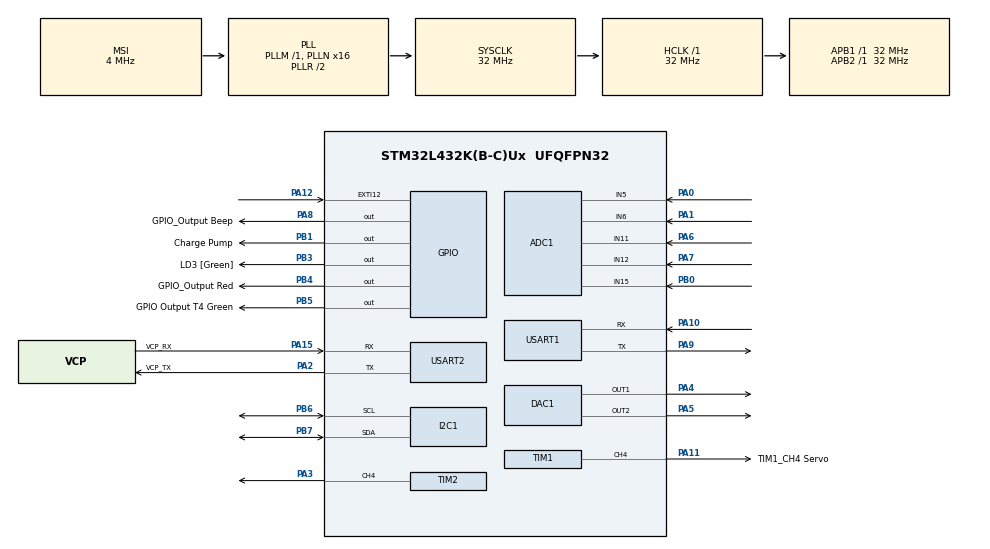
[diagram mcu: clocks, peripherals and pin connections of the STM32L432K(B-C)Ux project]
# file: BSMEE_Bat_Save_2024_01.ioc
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ADC1.Channel-0\#ChannelRegularConversion=ADC_CHANNEL_11
ADC1.Channel-1\#ChannelRegularConversion=ADC_CHANNEL_12
ADC1.Channel-2\#ChannelRegularConversion=ADC_CHANNEL_15
ADC1.Channel-3\#ChannelRegularConversion=ADC_CHANNEL_6
ADC1.Channel-4\#ChannelRegularConversion=ADC_CHANNEL_5
ADC1.ClockPrescaler=ADC_CLOCK_ASYNC_DIV16
ADC1.ContinuousConvMode=ENABLE
ADC1.DMAContinuousRequests=ENABLE
ADC1.EOCSelection=ADC_EOC_SEQ_CONV
ADC1.NbrOfConversion=5
ADC1.NbrOfConversionFlag=1
ADC1.OffsetNumber-0\#ChannelRegularConversion=ADC_OFFSET_NONE
ADC1.OffsetNumber-1\#ChannelRegularConversion=ADC_OFFSET_NONE
ADC1.OffsetNumber-2\#ChannelRegularConversion=ADC_OFFSET_NONE
ADC1.OffsetNumber-3\#ChannelRegularConversion=ADC_OFFSET_NONE
ADC1.OffsetNumber-4\#ChannelRegularConversion=ADC_OFFSET_NONE
ADC1.Overrun=ADC_OVR_DATA_OVERWRITTEN
ADC1.Rank-0\#ChannelRegularConversion=1
ADC1.Rank-1\#ChannelRegularConversion=2
ADC1.Rank-2\#ChannelRegularConversion=3
ADC1.Rank-3\#ChannelRegularConversion=4
ADC1.Rank-4\#ChannelRegularConversion=5
ADC1.SamplingTime-0\#ChannelRegularConversion=ADC_SAMPLETIME_247CYCLES_5
ADC1.SamplingTime-1\#ChannelRegularConversion=ADC_SAMPLETIME_247CYCLES_5
ADC1.SamplingTime-2\#ChannelRegularConversion=ADC_SAMPLETIME_247CYCLES_5
ADC1.SamplingTime-3\#ChannelRegularConversion=ADC_SAMPLETIME_247CYCLES_5
ADC1.SamplingTime-4\#ChannelRegularConversion=ADC_SAMPLETIME_247CYCLES_5
ADC1.master=1
DAC1.DAC_Channel-DAC_OUT2=DAC_CHANNEL_2
Dma.ADC1.4.Direction=DMA_PERIPH_TO_MEMORY
Dma.ADC1.4.Instance=DMA1_Channel1
Dma.ADC1.4.MemDataAlignment=DMA_MDATAALIGN_HALFWORD
Dma.ADC1.4.MemInc=DMA_MINC_ENABLE
Dma.ADC1.4.Mode=DMA_CIRCULAR
Dma.ADC1.4.PeriphDataAlignment=DMA_PDATAALIGN_HALFWORD
Dma.ADC1.4.PeriphInc=DMA_PINC_DISABLE
Dma.ADC1.4.Priority=DMA_PRIORITY_LOW
Dma.Request0=USART1_RX
Dma.Request1=USART1_TX
Dma.Request2=USART2_RX
Dma.Request3=USART2_TX
Dma.Request4=ADC1
Dma.USART1_RX.0.Direction=DMA_PERIPH_TO_MEMORY
Dma.USART1_RX.0.Instance=DMA1_Channel5
Dma.USART1_RX.0.MemDataAlignment=DMA_MDATAALIGN_BYTE
Dma.USART1_RX.0.MemInc=DMA_MINC_ENABLE
Dma.USART1_RX.0.Mode=DMA_NORMAL
Dma.USART1_RX.0.PeriphDataAlignment=DMA_PDATAALIGN_BYTE
Dma.USART1_RX.0.PeriphInc=DMA_PINC_DISABLE
Dma.USART1_RX.0.Priority=DMA_PRIORITY_LOW
Dma.USART1_TX.1.Direction=DMA_MEMORY_TO_PERIPH
Dma.USART1_TX.1.Instance=DMA1_Channel4
Dma.USART1_TX.1.MemDataAlignment=DMA_MDATAALIGN_BYTE
Dma.USART1_TX.1.MemInc=DMA_MINC_ENABLE
Dma.USART1_TX.1.Mode=DMA_NORMAL
Dma.USART1_TX.1.PeriphDataAlignment=DMA_PDATAALIGN_BYTE
Dma.USART1_TX.1.PeriphInc=DMA_PINC_DISABLE
Dma.USART1_TX.1.Priority=DMA_PRIORITY_LOW
Dma.USART2_RX.2.Direction=DMA_PERIPH_TO_MEMORY
Dma.USART2_RX.2.Instance=DMA1_Channel6
Dma.USART2_RX.2.MemDataAlignment=DMA_MDATAALIGN_BYTE
Dma.USART2_RX.2.MemInc=DMA_MINC_ENABLE
Dma.USART2_RX.2.Mode=DMA_NORMAL
Dma.USART2_RX.2.PeriphDataAlignment=DMA_PDATAALIGN_BYTE
Dma.USART2_RX.2.PeriphInc=DMA_PINC_DISABLE
Dma.USART2_RX.2.Priority=DMA_PRIORITY_LOW
Dma.USART2_TX.3.Direction=DMA_MEMORY_TO_PERIPH
Dma.USART2_TX.3.Instance=DMA1_Channel7
Dma.USART2_TX.3.MemDataAlignment=DMA_MDATAALIGN_BYTE
Dma.USART2_TX.3.MemInc=DMA_MINC_ENABLE
Dma.USART2_TX.3.Mode=DMA_NORMAL
Dma.USART2_TX.3.PeriphDataAlignment=DMA_PDATAALIGN_BYTE
Dma.USART2_TX.3.PeriphInc=DMA_PINC_DISABLE
Dma.USART2_TX.3.Priority=DMA_PRIORITY_LOW
I2C1.Timing=0x00707CBB
Mcu.Family=STM32L4
Mcu.Name=STM32L432K(B-C)Ux
Mcu.Package=UFQFPN32
NVIC.ADC1_IRQn=true\:0\:0\:false\:false\:true\:true\:true\:true
NVIC.DMA1_Channel1_IRQn=true\:0\:0\:false\:false\:true\:false\:true\:true
NVIC.DMA1_Channel4_IRQn=true\:0\:0\:false\:false\:true\:false\:true\:true
NVIC.DMA1_Channel5_IRQn=true\:0\:0\:false\:false\:true\:false\:true\:true
NVIC.DMA1_Channel6_IRQn=true\:0\:0\:false\:false\:true\:false\:true\:true
NVIC.DMA1_Channel7_IRQn=true\:0\:0\:false\:false\:true\:false\:true\:true
NVIC.PriorityGroup=NVIC_PRIORITYGROUP_4
NVIC.TIM6_DAC_IRQn=true\:0\:0\:false\:false\:true\:true\:true\:true
NVIC.USART1_IRQn=true\:0\:0\:false\:false\:true\:true\:true\:true
NVIC.USART2_IRQn=true\:0\:0\:false\:false\:true\:true\:true\:true
PA0.Signal=ADCx_IN5
PA1.Signal=ADCx_IN6
PA10.Mode=Asynchronous
PA10.Signal=USART1_RX
PA11.GPIO_Label=TIM1_CH4 Servo
PA11.Signal=S_TIM1_CH4
PA12.Signal=GPXTI12
PA13\ (JTMS-SWDIO).GPIO_Label=SWDIO
PA13\ (JTMS-SWDIO).Mode=Serial_Wire
PA13\ (JTMS-SWDIO).Signal=SYS_JTMS-SWDIO
PA14\ (JTCK-SWCLK).GPIO_Label=SWCLK
PA14\ (JTCK-SWCLK).Mode=Serial_Wire
PA14\ (JTCK-SWCLK).Signal=SYS_JTCK-SWCLK
PA15\ (JTDI).GPIO_Label=VCP_RX
PA15\ (JTDI).Mode=Asynchronous
PA15\ (JTDI).Signal=USART2_RX
PA2.GPIO_Label=VCP_TX
PA2.Mode=Asynchronous
PA2.Signal=USART2_TX
PA3.Signal=S_TIM2_CH4
PA4.Signal=COMP_DAC11_group
PA5.Signal=COMP_DAC12_group
PA6.Signal=ADCx_IN11
PA7.Signal=ADCx_IN12
PA8.GPIO_Label=GPIO_Output Beep
PA8.Signal=GPIO_Output
PA9.Mode=Asynchronous
PA9.Signal=USART1_TX
PB0.Signal=ADCx_IN15
PB1.GPIO_Label=Charge Pump
PB1.Signal=GPIO_Output
PB3\ (JTDO-TRACESWO).GPIO_Label=LD3 [Green]
PB3\ (JTDO-TRACESWO).Signal=GPIO_Output
PB4\ (NJTRST).GPIO_Label=GPIO_Output Red
PB4\ (NJTRST).Signal=GPIO_Output
PB5.GPIO_Label=GPIO Output T4 Green
PB5.Signal=GPIO_Output
PB6.Mode=I2C
PB6.Signal=I2C1_SCL
PB7.Mode=I2C
PB7.Signal=I2C1_SDA
PC14-OSC32_IN\ (PC14).Mode=LSE-External-Oscillator
PC14-OSC32_IN\ (PC14).Signal=RCC_OSC32_IN
PC15-OSC32_OUT\ (PC15).Mode=LSE-External-Oscillator
PC15-OSC32_OUT\ (PC15).Signal=RCC_OSC32_OUT
ProjectManager.HeapSize=0x200
ProjectManager.StackSize=0x400
ProjectManager.TargetToolchain=STM32CubeIDE
RCC.ADCFreq_Value=32000000
RCC.AHBFreq_Value=32000000
RCC.APB1Freq_Value=32000000
RCC.APB1TimFreq_Value=32000000
RCC.APB2Freq_Value=32000000
RCC.APB2TimFreq_Value=32000000
RCC.CortexFreq_Value=32000000
RCC.HCLKFreq_Value=32000000
RCC.HSE_VALUE=8000000
RCC.HSI16_VALUE=16000000
RCC.HSI48_VALUE=48000000
RCC.HSI_VALUE=16000000
RCC.MSI_VALUE=4000000
RCC.PLLMUL=RCC_PLLMUL_4
RCC.PLLN=16
RCC.PLLSAI1N=16
RCC.SYSCLKFreq_VALUE=32000000
RCC.SYSCLKSource=RCC_SYSCLKSOURCE_PLLCLK
RCC.USBFreq_Value=32000000
RCC.VCOOutputFreq_Value=64000000
SH.ADCx_IN11.0=ADC1_IN11,IN11-Single-Ended
SH.ADCx_IN12.0=ADC1_IN12,IN12-Single-Ended
SH.ADCx_IN15.0=ADC1_IN15,IN15-Single-Ended
SH.ADCx_IN5.0=ADC1_IN5,IN5-Single-Ended
SH.ADCx_IN6.0=ADC1_IN6,IN6-Single-Ended
SH.COMP_DAC11_group.0=DAC1_OUT1,DAC_OUT1
SH.COMP_DAC12_group.0=DAC1_OUT2,DAC_OUT2
SH.S_TIM1_CH4.0=TIM1_CH4,PWM Generation4 CH4
SH.S_TIM2_CH4.0=TIM2_CH4,PWM Generation4 CH4
TIM1.Channel-PWM\ Generation4\ CH4=TIM_CHANNEL_4
TIM2.AutoReloadPreload=TIM_AUTORELOAD_PRELOAD_ENABLE
TIM2.Channel-PWM\ Generation4\ CH4=TIM_CHANNEL_4
TIM2.OCPolarity_4=TIM_OCPOLARITY_LOW
TIM2.Period=1023
TIM2.Prescaler=1
TIM2.Pulse-PWM\ Generation4\ CH4=100
TIM6.AutoReloadPreload=TIM_AUTORELOAD_PRELOAD_ENABLE
TIM6.Period=1000 - 1
TIM6.Prescaler=32 - 1
USART1.VirtualMode-Asynchronous=VM_ASYNC
USART2.VirtualMode-Asynchronous=VM_ASYNC
VP_RTC_VS_RTC_Activate.Mode=RTC_Enabled
VP_RTC_VS_RTC_Calendar.Mode=RTC_Calendar
VP_TIM2_VS_ClockSourceINT.Mode=Internal
VP_TIM6_VS_ClockSourceINT.Mode=Enable_Timer
board=NUCLEO-L432KC

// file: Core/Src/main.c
/* USER CODE BEGIN Header */
/**
 *  Jon Freeman B Eng Hons
 *
 * WARNING
 * Code created using STM32CubeIDE from ST Microelectronics.
 * THIS FILE IS A MIX OF MACHINE-GENERATED / MAN-MADE CODE including most of the startup code
 *
 * YOU ARE STRONGLY ADVISED NOT TO EDIT THIS FILE
 *
  ******************************************************************************
  * @file           : main.c
  * @brief          : Main program body
  ******************************************************************************
  * @attention
  *
  * Copyright (c) 2024 STMicroelectronics.
  * All rights reserved.
  *
  * This software is licensed under terms that can be found in the LICENSE file
  * in the root directory of this software component.
  * If no LICENSE file comes with this software, it is provided AS-IS.
  *
  ******************************************************************************
  */
/* USER CODE END Header */
#include "main.h"

/* USER CODE BEGIN Includes */
#include	<stdbool.h>

/* USER CODE END Includes */

ADC_HandleTypeDef hadc1;
DMA_HandleTypeDef hdma_adc1;

DAC_HandleTypeDef hdac1;

I2C_HandleTypeDef hi2c1;

RTC_HandleTypeDef hrtc;

TIM_HandleTypeDef htim1;
TIM_HandleTypeDef htim2;
TIM_HandleTypeDef htim6;

UART_HandleTypeDef huart1;
UART_HandleTypeDef huart2;
DMA_HandleTypeDef hdma_usart1_rx;
DMA_HandleTypeDef hdma_usart1_tx;
DMA_HandleTypeDef hdma_usart2_rx;
DMA_HandleTypeDef hdma_usart2_tx;

void SystemClock_Config(void);
static void MX_GPIO_Init(void);
static void MX_DMA_Init(void);
static void MX_USART2_UART_Init(void);
static void MX_ADC1_Init(void);
static void MX_DAC1_Init(void);
static void MX_I2C1_Init(void);
static void MX_USART1_UART_Init(void);
static void MX_TIM1_Init(void);
static void MX_TIM2_Init(void);
static void MX_TIM6_Init(void);
static void MX_RTC_Init(void);
/* USER CODE BEGIN PFP */
extern	void	ForeverLoop	()	;

/* USER CODE END PFP */

int main(void)
{

  /* MCU Configuration--------------------------------------------------------*/

  /* Reset of all peripherals, Initializes the Flash interface and the Systick. */
  HAL_Init();

  /* Configure the system clock */
  SystemClock_Config();

  /* Initialize all configured peripherals */
  MX_GPIO_Init();
  MX_DMA_Init();
  MX_USART2_UART_Init();
  MX_ADC1_Init();
  MX_DAC1_Init();
  MX_I2C1_Init();
  MX_USART1_UART_Init();
  MX_TIM1_Init();
  MX_TIM2_Init();
  MX_TIM6_Init();
  MX_RTC_Init();
  /* USER CODE BEGIN 2 */
  HAL_TIM_Base_Start_IT(&htim6);	//	Need this to start timer

  ForeverLoop	();		//	Leave main.c, into 'C++', never to return

  /* USER CODE END 2 */

  /* Infinite loop */
  while (1)
  {

  }
}

void SystemClock_Config(void)
{
  RCC_OscInitTypeDef RCC_OscInitStruct = {0};
  RCC_ClkInitTypeDef RCC_ClkInitStruct = {0};

  /** Configure the main internal regulator output voltage
  */
  if (HAL_PWREx_ControlVoltageScaling(PWR_REGULATOR_VOLTAGE_SCALE1) != HAL_OK)
  {
    Error_Handler();
  }

  /** Configure LSE Drive Capability
  */
  HAL_PWR_EnableBkUpAccess();
  __HAL_RCC_LSEDRIVE_CONFIG(RCC_LSEDRIVE_LOW);

  /** Initializes the RCC Oscillators according to the specified parameters
  * in the RCC_OscInitTypeDef structure.
  */
  RCC_OscInitStruct.OscillatorType = RCC_OSCILLATORTYPE_LSI|RCC_OSCILLATORTYPE_LSE
                              |RCC_OSCILLATORTYPE_MSI;
  RCC_OscInitStruct.LSEState = RCC_LSE_ON;
  RCC_OscInitStruct.LSIState = RCC_LSI_ON;
  RCC_OscInitStruct.MSIState = RCC_MSI_ON;
  RCC_OscInitStruct.MSICalibrationValue = 0;
  RCC_OscInitStruct.MSIClockRange = RCC_MSIRANGE_6;
  RCC_OscInitStruct.PLL.PLLState = RCC_PLL_ON;
  RCC_OscInitStruct.PLL.PLLSource = RCC_PLLSOURCE_MSI;
  RCC_OscInitStruct.PLL.PLLM = 1;
  RCC_OscInitStruct.PLL.PLLN = 16;
  RCC_OscInitStruct.PLL.PLLP = RCC_PLLP_DIV7;
  RCC_OscInitStruct.PLL.PLLQ = RCC_PLLQ_DIV2;
  RCC_OscInitStruct.PLL.PLLR = RCC_PLLR_DIV2;
  if (HAL_RCC_OscConfig(&RCC_OscInitStruct) != HAL_OK)
  {
    Error_Handler();
  }

  /** Initializes the CPU, AHB and APB buses clocks
  */
  RCC_ClkInitStruct.ClockType = RCC_CLOCKTYPE_HCLK|RCC_CLOCKTYPE_SYSCLK
                              |RCC_CLOCKTYPE_PCLK1|RCC_CLOCKTYPE_PCLK2;
  RCC_ClkInitStruct.SYSCLKSource = RCC_SYSCLKSOURCE_PLLCLK;
  RCC_ClkInitStruct.AHBCLKDivider = RCC_SYSCLK_DIV1;
  RCC_ClkInitStruct.APB1CLKDivider = RCC_HCLK_DIV1;
  RCC_ClkInitStruct.APB2CLKDivider = RCC_HCLK_DIV1;

  if (HAL_RCC_ClockConfig(&RCC_ClkInitStruct, FLASH_LATENCY_1) != HAL_OK)
  {
    Error_Handler();
  }

  /** Enable MSI Auto calibration
  */
  HAL_RCCEx_EnableMSIPLLMode();
}

static void MX_ADC1_Init(void)
{

  ADC_ChannelConfTypeDef sConfig = {0};

  /** Common config
  */
  hadc1.Instance = ADC1;
  hadc1.Init.ClockPrescaler = ADC_CLOCK_ASYNC_DIV16;
  hadc1.Init.Resolution = ADC_RESOLUTION_12B;
  hadc1.Init.DataAlign = ADC_DATAALIGN_RIGHT;
  hadc1.Init.ScanConvMode = ADC_SCAN_ENABLE;
  hadc1.Init.EOCSelection = ADC_EOC_SEQ_CONV;
  hadc1.Init.LowPowerAutoWait = DISABLE;
  hadc1.Init.ContinuousConvMode = ENABLE;
  hadc1.Init.NbrOfConversion = 5;
  hadc1.Init.DiscontinuousConvMode = DISABLE;
  hadc1.Init.ExternalTrigConv = ADC_SOFTWARE_START;
  hadc1.Init.ExternalTrigConvEdge = ADC_EXTERNALTRIGCONVEDGE_NONE;
  hadc1.Init.DMAContinuousRequests = ENABLE;
  hadc1.Init.Overrun = ADC_OVR_DATA_OVERWRITTEN;
  hadc1.Init.OversamplingMode = DISABLE;
  if (HAL_ADC_Init(&hadc1) != HAL_OK)
  {
    Error_Handler();
  }

  /** Configure Regular Channel
  */
  sConfig.Channel = ADC_CHANNEL_11;
  sConfig.Rank = ADC_REGULAR_RANK_1;
  sConfig.SamplingTime = ADC_SAMPLETIME_247CYCLES_5;
  sConfig.SingleDiff = ADC_SINGLE_ENDED;
  sConfig.OffsetNumber = ADC_OFFSET_NONE;
  sConfig.Offset = 0;
  if (HAL_ADC_ConfigChannel(&hadc1, &sConfig) != HAL_OK)
  {
    Error_Handler();
  }

  /** Configure Regular Channel
  */
  sConfig.Channel = ADC_CHANNEL_12;
  sConfig.Rank = ADC_REGULAR_RANK_2;
  if (HAL_ADC_ConfigChannel(&hadc1, &sConfig) != HAL_OK)
  {
    Error_Handler();
  }

  /** Configure Regular Channel
  */
  sConfig.Channel = ADC_CHANNEL_15;
  sConfig.Rank = ADC_REGULAR_RANK_3;
  if (HAL_ADC_ConfigChannel(&hadc1, &sConfig) != HAL_OK)
  {
    Error_Handler();
  }

  /** Configure Regular Channel
  */
  sConfig.Channel = ADC_CHANNEL_6;
  sConfig.Rank = ADC_REGULAR_RANK_4;
  if (HAL_ADC_ConfigChannel(&hadc1, &sConfig) != HAL_OK)
  {
    Error_Handler();
  }

  /** Configure Regular Channel
  */
  sConfig.Channel = ADC_CHANNEL_5;
  sConfig.Rank = ADC_REGULAR_RANK_5;
  if (HAL_ADC_ConfigChannel(&hadc1, &sConfig) != HAL_OK)
  {
    Error_Handler();
  }

}

static void MX_DAC1_Init(void)
{

  DAC_ChannelConfTypeDef sConfig = {0};

  /** DAC Initialization
  */
  hdac1.Instance = DAC1;
  if (HAL_DAC_Init(&hdac1) != HAL_OK)
  {
    Error_Handler();
  }

  /** DAC channel OUT1 config
  */
  sConfig.DAC_SampleAndHold = DAC_SAMPLEANDHOLD_DISABLE;
  sConfig.DAC_Trigger = DAC_TRIGGER_NONE;
  sConfig.DAC_OutputBuffer = DAC_OUTPUTBUFFER_ENABLE;
  sConfig.DAC_ConnectOnChipPeripheral = DAC_CHIPCONNECT_DISABLE;
  sConfig.DAC_UserTrimming = DAC_TRIMMING_FACTORY;
  if (HAL_DAC_ConfigChannel(&hdac1, &sConfig, DAC_CHANNEL_1) != HAL_OK)
  {
    Error_Handler();
  }

  /** DAC channel OUT2 config
  */
  if (HAL_DAC_ConfigChannel(&hdac1, &sConfig, DAC_CHANNEL_2) != HAL_OK)
  {
    Error_Handler();
  }

}

static void MX_I2C1_Init(void)
{

  hi2c1.Instance = I2C1;
  hi2c1.Init.Timing = 0x00707CBB;
  hi2c1.Init.OwnAddress1 = 0;
  hi2c1.Init.AddressingMode = I2C_ADDRESSINGMODE_7BIT;
  hi2c1.Init.DualAddressMode = I2C_DUALADDRESS_DISABLE;
  hi2c1.Init.OwnAddress2 = 0;
  hi2c1.Init.OwnAddress2Masks = I2C_OA2_NOMASK;
  hi2c1.Init.GeneralCallMode = I2C_GENERALCALL_DISABLE;
  hi2c1.Init.NoStretchMode = I2C_NOSTRETCH_DISABLE;
  if (HAL_I2C_Init(&hi2c1) != HAL_OK)
  {
    Error_Handler();
  }

  /** Configure Analogue filter
  */
  if (HAL_I2CEx_ConfigAnalogFilter(&hi2c1, I2C_ANALOGFILTER_ENABLE) != HAL_OK)
  {
    Error_Handler();
  }

  /** Configure Digital filter
  */
  if (HAL_I2CEx_ConfigDigitalFilter(&hi2c1, 0) != HAL_OK)
  {
    Error_Handler();
  }

}

static void MX_RTC_Init(void)
{

  RTC_TimeTypeDef sTime = {0};
  RTC_DateTypeDef sDate = {0};

  /** Initialize RTC Only
  */
  hrtc.Instance = RTC;
  hrtc.Init.HourFormat = RTC_HOURFORMAT_24;
  hrtc.Init.AsynchPrediv = 127;
  hrtc.Init.SynchPrediv = 255;
  hrtc.Init.OutPut = RTC_OUTPUT_DISABLE;
  hrtc.Init.OutPutRemap = RTC_OUTPUT_REMAP_NONE;
  hrtc.Init.OutPutPolarity = RTC_OUTPUT_POLARITY_HIGH;
  hrtc.Init.OutPutType = RTC_OUTPUT_TYPE_OPENDRAIN;
  if (HAL_RTC_Init(&hrtc) != HAL_OK)
  {
    Error_Handler();
  }

  /** Initialize RTC and set the Time and Date
  */
  sTime.Hours = 0x0;
  sTime.Minutes = 0x0;
  sTime.Seconds = 0x0;
  sTime.DayLightSaving = RTC_DAYLIGHTSAVING_NONE;
  sTime.StoreOperation = RTC_STOREOPERATION_RESET;
  if (HAL_RTC_SetTime(&hrtc, &sTime, RTC_FORMAT_BCD) != HAL_OK)
  {
    Error_Handler();
  }
  sDate.WeekDay = RTC_WEEKDAY_MONDAY;
  sDate.Month = RTC_MONTH_JANUARY;
  sDate.Date = 0x1;
  sDate.Year = 0x0;

  if (HAL_RTC_SetDate(&hrtc, &sDate, RTC_FORMAT_BCD) != HAL_OK)
  {
    Error_Handler();
  }

}

static void MX_TIM1_Init(void)
{

  TIM_MasterConfigTypeDef sMasterConfig = {0};
  TIM_OC_InitTypeDef sConfigOC = {0};
  TIM_BreakDeadTimeConfigTypeDef sBreakDeadTimeConfig = {0};

  htim1.Instance = TIM1;
  htim1.Init.Prescaler = 0;
  htim1.Init.CounterMode = TIM_COUNTERMODE_UP;
  htim1.Init.Period = 65535;
  htim1.Init.ClockDivision = TIM_CLOCKDIVISION_DIV1;
  htim1.Init.RepetitionCounter = 0;
  htim1.Init.AutoReloadPreload = TIM_AUTORELOAD_PRELOAD_DISABLE;
  if (HAL_TIM_PWM_Init(&htim1) != HAL_OK)
  {
    Error_Handler();
  }
  sMasterConfig.MasterOutputTrigger = TIM_TRGO_RESET;
  sMasterConfig.MasterOutputTrigger2 = TIM_TRGO2_RESET;
  sMasterConfig.MasterSlaveMode = TIM_MASTERSLAVEMODE_DISABLE;
  if (HAL_TIMEx_MasterConfigSynchronization(&htim1, &sMasterConfig) != HAL_OK)
  {
    Error_Handler();
  }
  sConfigOC.OCMode = TIM_OCMODE_PWM1;
  sConfigOC.Pulse = 0;
  sConfigOC.OCPolarity = TIM_OCPOLARITY_HIGH;
  sConfigOC.OCFastMode = TIM_OCFAST_DISABLE;
  sConfigOC.OCIdleState = TIM_OCIDLESTATE_RESET;
  sConfigOC.OCNIdleState = TIM_OCNIDLESTATE_RESET;
  if (HAL_TIM_PWM_ConfigChannel(&htim1, &sConfigOC, TIM_CHANNEL_4) != HAL_OK)
  {
    Error_Handler();
  }
  sBreakDeadTimeConfig.OffStateRunMode = TIM_OSSR_DISABLE;
  sBreakDeadTimeConfig.OffStateIDLEMode = TIM_OSSI_DISABLE;
  sBreakDeadTimeConfig.LockLevel = TIM_LOCKLEVEL_OFF;
  sBreakDeadTimeConfig.DeadTime = 0;
  sBreakDeadTimeConfig.BreakState = TIM_BREAK_DISABLE;
  sBreakDeadTimeConfig.BreakPolarity = TIM_BREAKPOLARITY_HIGH;
  sBreakDeadTimeConfig.BreakFilter = 0;
  sBreakDeadTimeConfig.Break2State = TIM_BREAK2_DISABLE;
  sBreakDeadTimeConfig.Break2Polarity = TIM_BREAK2POLARITY_HIGH;
  sBreakDeadTimeConfig.Break2Filter = 0;
  sBreakDeadTimeConfig.AutomaticOutput = TIM_AUTOMATICOUTPUT_DISABLE;
  if (HAL_TIMEx_ConfigBreakDeadTime(&htim1, &sBreakDeadTimeConfig) != HAL_OK)
  {
    Error_Handler();
  }
  HAL_TIM_MspPostInit(&htim1);

}

static void MX_TIM2_Init(void)
{

  TIM_ClockConfigTypeDef sClockSourceConfig = {0};
  TIM_MasterConfigTypeDef sMasterConfig = {0};
  TIM_OC_InitTypeDef sConfigOC = {0};

  htim2.Instance = TIM2;
  htim2.Init.Prescaler = 1;
  htim2.Init.CounterMode = TIM_COUNTERMODE_UP;
  htim2.Init.Period = 1023;
  htim2.Init.ClockDivision = TIM_CLOCKDIVISION_DIV1;
  htim2.Init.AutoReloadPreload = TIM_AUTORELOAD_PRELOAD_ENABLE;
  if (HAL_TIM_Base_Init(&htim2) != HAL_OK)
  {
    Error_Handler();
  }
  sClockSourceConfig.ClockSource = TIM_CLOCKSOURCE_INTERNAL;
  if (HAL_TIM_ConfigClockSource(&htim2, &sClockSourceConfig) != HAL_OK)
  {
    Error_Handler();
  }
  if (HAL_TIM_PWM_Init(&htim2) != HAL_OK)
  {
    Error_Handler();
  }
  sMasterConfig.MasterOutputTrigger = TIM_TRGO_RESET;
  sMasterConfig.MasterSlaveMode = TIM_MASTERSLAVEMODE_DISABLE;
  if (HAL_TIMEx_MasterConfigSynchronization(&htim2, &sMasterConfig) != HAL_OK)
  {
    Error_Handler();
  }
  sConfigOC.OCMode = TIM_OCMODE_PWM1;
  sConfigOC.Pulse = 100;
  sConfigOC.OCPolarity = TIM_OCPOLARITY_LOW;
  sConfigOC.OCFastMode = TIM_OCFAST_DISABLE;
  if (HAL_TIM_PWM_ConfigChannel(&htim2, &sConfigOC, TIM_CHANNEL_4) != HAL_OK)
  {
    Error_Handler();
  }
  HAL_TIM_MspPostInit(&htim2);

}

static void MX_TIM6_Init(void)
{

  TIM_MasterConfigTypeDef sMasterConfig = {0};

  htim6.Instance = TIM6;
  htim6.Init.Prescaler = 32 - 1;
  htim6.Init.CounterMode = TIM_COUNTERMODE_UP;
  htim6.Init.Period = 1000 - 1;
  htim6.Init.AutoReloadPreload = TIM_AUTORELOAD_PRELOAD_ENABLE;
  if (HAL_TIM_Base_Init(&htim6) != HAL_OK)
  {
    Error_Handler();
  }
  sMasterConfig.MasterOutputTrigger = TIM_TRGO_RESET;
  sMasterConfig.MasterSlaveMode = TIM_MASTERSLAVEMODE_DISABLE;
  if (HAL_TIMEx_MasterConfigSynchronization(&htim6, &sMasterConfig) != HAL_OK)
  {
    Error_Handler();
  }

}

static void MX_USART1_UART_Init(void)
{

  huart1.Instance = USART1;
  huart1.Init.BaudRate = 115200;
  huart1.Init.WordLength = UART_WORDLENGTH_8B;
  huart1.Init.StopBits = UART_STOPBITS_1;
  huart1.Init.Parity = UART_PARITY_NONE;
  huart1.Init.Mode = UART_MODE_TX_RX;
  huart1.Init.HwFlowCtl = UART_HWCONTROL_NONE;
  huart1.Init.OverSampling = UART_OVERSAMPLING_16;
  huart1.Init.OneBitSampling = UART_ONE_BIT_SAMPLE_DISABLE;
  huart1.AdvancedInit.AdvFeatureInit = UART_ADVFEATURE_NO_INIT;
  if (HAL_UART_Init(&huart1) != HAL_OK)
  {
    Error_Handler();
  }

}

static void MX_USART2_UART_Init(void)
{

  huart2.Instance = USART2;
  huart2.Init.BaudRate = 115200;
  huart2.Init.WordLength = UART_WORDLENGTH_8B;
  huart2.Init.StopBits = UART_STOPBITS_1;
  huart2.Init.Parity = UART_PARITY_NONE;
  huart2.Init.Mode = UART_MODE_TX_RX;
  huart2.Init.HwFlowCtl = UART_HWCONTROL_NONE;
  huart2.Init.OverSampling = UART_OVERSAMPLING_16;
  huart2.Init.OneBitSampling = UART_ONE_BIT_SAMPLE_DISABLE;
  huart2.AdvancedInit.AdvFeatureInit = UART_ADVFEATURE_NO_INIT;
  if (HAL_UART_Init(&huart2) != HAL_OK)
  {
    Error_Handler();
  }

}

static void MX_DMA_Init(void)
{

  /* DMA controller clock enable */
  __HAL_RCC_DMA1_CLK_ENABLE();

  /* DMA interrupt init */
  /* DMA1_Channel1_IRQn interrupt configuration */
  HAL_NVIC_SetPriority(DMA1_Channel1_IRQn, 0, 0);
  HAL_NVIC_EnableIRQ(DMA1_Channel1_IRQn);
  /* DMA1_Channel4_IRQn interrupt configuration */
  HAL_NVIC_SetPriority(DMA1_Channel4_IRQn, 0, 0);
  HAL_NVIC_EnableIRQ(DMA1_Channel4_IRQn);
  /* DMA1_Channel5_IRQn interrupt configuration */
  HAL_NVIC_SetPriority(DMA1_Channel5_IRQn, 0, 0);
  HAL_NVIC_EnableIRQ(DMA1_Channel5_IRQn);
  /* DMA1_Channel6_IRQn interrupt configuration */
  HAL_NVIC_SetPriority(DMA1_Channel6_IRQn, 0, 0);
  HAL_NVIC_EnableIRQ(DMA1_Channel6_IRQn);
  /* DMA1_Channel7_IRQn interrupt configuration */
  HAL_NVIC_SetPriority(DMA1_Channel7_IRQn, 0, 0);
  HAL_NVIC_EnableIRQ(DMA1_Channel7_IRQn);

}

static void MX_GPIO_Init(void)
{
  GPIO_InitTypeDef GPIO_InitStruct = {0};

  /* GPIO Ports Clock Enable */
  __HAL_RCC_GPIOC_CLK_ENABLE();
  __HAL_RCC_GPIOA_CLK_ENABLE();
  __HAL_RCC_GPIOB_CLK_ENABLE();

  /*Configure GPIO pin Output Level */
  HAL_GPIO_WritePin(GPIOB, Charge_Pump_Pin|LD3_Pin|GPIO_Output_Red_Pin|GPIO_Output_T4_Green_Pin, GPIO_PIN_RESET);

  /*Configure GPIO pin Output Level */
  HAL_GPIO_WritePin(GPIO_Output_Beep_GPIO_Port, GPIO_Output_Beep_Pin, GPIO_PIN_RESET);

  /*Configure GPIO pins : Charge_Pump_Pin LD3_Pin GPIO_Output_Red_Pin GPIO_Output_T4_Green_Pin */
  GPIO_InitStruct.Pin = Charge_Pump_Pin|LD3_Pin|GPIO_Output_Red_Pin|GPIO_Output_T4_Green_Pin;
  GPIO_InitStruct.Mode = GPIO_MODE_OUTPUT_PP;
  GPIO_InitStruct.Pull = GPIO_NOPULL;
  GPIO_InitStruct.Speed = GPIO_SPEED_FREQ_LOW;
  HAL_GPIO_Init(GPIOB, &GPIO_InitStruct);

  /*Configure GPIO pin : GPIO_Output_Beep_Pin */
  GPIO_InitStruct.Pin = GPIO_Output_Beep_Pin;
  GPIO_InitStruct.Mode = GPIO_MODE_OUTPUT_PP;
  GPIO_InitStruct.Pull = GPIO_NOPULL;
  GPIO_InitStruct.Speed = GPIO_SPEED_FREQ_LOW;
  HAL_GPIO_Init(GPIO_Output_Beep_GPIO_Port, &GPIO_InitStruct);

  /*Configure GPIO pin : PA12 */
  GPIO_InitStruct.Pin = GPIO_PIN_12;
  GPIO_InitStruct.Mode = GPIO_MODE_IT_RISING;
  GPIO_InitStruct.Pull = GPIO_NOPULL;
  HAL_GPIO_Init(GPIOA, &GPIO_InitStruct);

}

/* USER CODE BEGIN 4 */
//	Callback: timer has reset
/*
void	HAL_TIM_PeriodElapsedCallback(TIM_HandleTypeDef *htim)
{	//	check for timer 6
	if	(htim == &htim6)	{
		timer_1ms_flag = true;
		millisecs++;		//	Global count of milli seconds since power-up
		forever_loop_timer++;
		slow_loop_timer++;
	}
}
*/

/* USER CODE END 4 */

void Error_Handler(void)
{
  __disable_irq();
  while (1)
  {
  }
}
